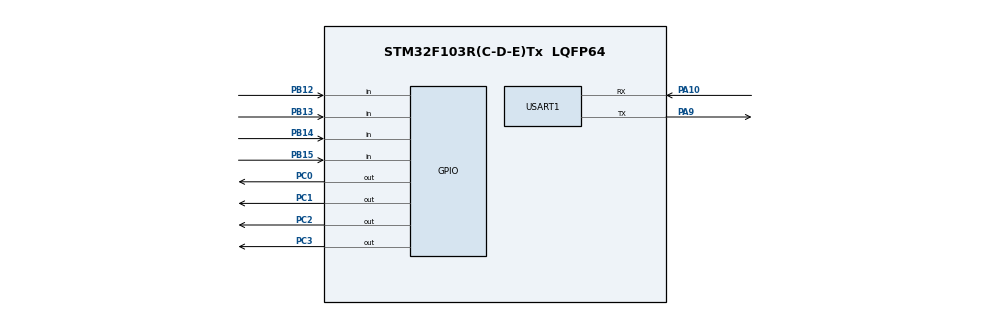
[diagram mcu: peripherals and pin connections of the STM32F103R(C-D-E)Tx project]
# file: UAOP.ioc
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Mcu.Family=STM32F1
Mcu.Name=STM32F103R(C-D-E)Tx
Mcu.Package=LQFP64
NVIC.PriorityGroup=NVIC_PRIORITYGROUP_4
PA10.Mode=Asynchronous
PA10.Signal=USART1_RX
PA9.Mode=Asynchronous
PA9.Signal=USART1_TX
PB12.Signal=GPIO_Input
PB13.Signal=GPIO_Input
PB14.Signal=GPIO_Input
PB15.Signal=GPIO_Input
PC0.PinState=GPIO_PIN_SET
PC0.Signal=GPIO_Output
PC1.PinState=GPIO_PIN_SET
PC1.Signal=GPIO_Output
PC2.PinState=GPIO_PIN_SET
PC2.Signal=GPIO_Output
PC3.PinState=GPIO_PIN_SET
PC3.Signal=GPIO_Output
PD0-OSC_IN.Signal=RCC_OSC_IN
ProjectManager.HeapSize=0x200
ProjectManager.StackSize=0x400
ProjectManager.TargetToolchain=STM32CubeIDE
RCC.APB1Freq_Value=8000000
RCC.APB2Freq_Value=8000000
USART1.VirtualMode=VM_ASYNC
VP_SYS_VS_ND.Mode=No_Debug
VP_TIM1_VS_ClockSourceINT.Mode=Internal
VP_TIM1_VS_ClockSourceITR.Mode=TriggerSource_ITR0
VP_TIM1_VS_ControllerModeTrigger.Mode=Trigger Mode
board=custom

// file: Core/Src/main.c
/* USER CODE BEGIN Header */
/**
  ******************************************************************************
  * @file           : main.c
  * @brief          : Main program body
  ******************************************************************************
  * @attention
  *
  * Copyright (c) 2024 STMicroelectronics.
  * All rights reserved.
  *
  * This software is licensed under terms that can be found in the LICENSE file
  * in the root directory of this software component.
  * If no LICENSE file comes with this software, it is provided AS-IS.
  *
  ******************************************************************************
  */
/* USER CODE END Header */
#include "main.h"
#include "stm32f1xx_hal.h"
#include <string.h>
#include <stdio.h>
#include <ctype.h>

TIM_HandleTypeDef htim1;

UART_HandleTypeDef huart1;

/* USER CODE BEGIN PV */
uint32_t time_star = 0;
uint32_t time_end = 0;
uint32_t time_delta = 0;
/* USER CODE END PV */

void SystemClock_Config(void);
static void MX_GPIO_Init(void);
static void MX_TIM1_Init(void);
static void MX_USART1_UART_Init(void);
void trim_whitespace(char *str);

/* USER CODE BEGIN 0 */
#define NUM_SAIDAS 8
#define NUM_ENTRADAS 4

const char *OUT[NUM_SAIDAS] = {"OUT1_ON", "OUT1_OFF", "OUT2_ON", "OUT2_OFF", "OUT3_ON", "OUT3_OFF", "OUT4_ON", "OUT4_OFF"};
const char *INT[NUM_ENTRADAS] = {"IN1", "IN2", "IN3", "IN4"};

/* USER CODE END 0 */

int main(void)
{

  /* MCU Configuration--------------------------------------------------------*/

  /* Reset of all peripherals, Initializes the Flash interface and the Systick. */
  HAL_Init();

  /* Configure the system clock */
  SystemClock_Config();

  /* Initialize all configured peripherals */
  MX_GPIO_Init();
  MX_TIM1_Init();
  MX_USART1_UART_Init();

  /* USER CODE BEGIN 2 */

  char buffer[100];
  uint8_t dado;
  int index = 0;

  HAL_TIM_Base_Start(&htim1);
  /* USER CODE END 2 */

  /* Infinite loop */
  while (1)
  {
	HAL_UART_Receive(&huart1, &dado, 1, HAL_MAX_DELAY);

	if (dado == '\r') // Verifica se é o fim da palavra (Enter)
	{
		buffer[index] = '\0'; // Termina a string
		trim_whitespace(buffer); // Remove espaços em branco e caracteres invisíveis

		int found = 0;
		for (int i = 0; i < NUM_SAIDAS; i++)
		{
			if (strstr(buffer, OUT[i]) != NULL)
			{
				// Ações para as saídas
				switch (i)
				{
					case 0:
						HAL_GPIO_WritePin(GPIOC, GPIO_PIN_0, GPIO_PIN_RESET); //liga saida out1
						break;
					case 1:
						HAL_GPIO_WritePin(GPIOC, GPIO_PIN_0, GPIO_PIN_SET); //desliga saida out1
						break;
					case 2:
						HAL_GPIO_WritePin(GPIOC, GPIO_PIN_1, GPIO_PIN_RESET); //liga saida out2
						break;
					case 3:
						HAL_GPIO_WritePin(GPIOC, GPIO_PIN_1, GPIO_PIN_SET); //desliga saida out2
						break;
					case 4:
						HAL_GPIO_WritePin(GPIOC, GPIO_PIN_2, GPIO_PIN_RESET); //liga saida out3
						break;
					case 5:
						HAL_GPIO_WritePin(GPIOC, GPIO_PIN_2, GPIO_PIN_SET); //desliga saida out3
						break;
					case 6:
						HAL_GPIO_WritePin(GPIOC, GPIO_PIN_3, GPIO_PIN_RESET); //liga saida out4
						break;
					case 7:
						HAL_GPIO_WritePin(GPIOC, GPIO_PIN_3, GPIO_PIN_SET); //desliga saida out4
						break;
					default:
						break;
				}
				char mensagem[50];
				snprintf(mensagem, sizeof(mensagem), "OK: %d\r\n", i);
				HAL_UART_Transmit(&huart1, (uint8_t*)mensagem, strlen(mensagem), HAL_MAX_DELAY);
				found = 1;
				break;
				}
			}

			// Ações para as entradas
			for (int i = 0; i < NUM_ENTRADAS; i++)
			{
				if (strstr(buffer, INT[i]) != NULL)
				{
				GPIO_PinState pinState;
				switch (i)
					{
					case 0:
						pinState = HAL_GPIO_ReadPin(GPIOB, GPIO_PIN_12); // Leitura da entrada IN1
						break;
					case 1:
						pinState = HAL_GPIO_ReadPin(GPIOB, GPIO_PIN_13); // Leitura da entrada IN2
						break;
					case 2:
						pinState = HAL_GPIO_ReadPin(GPIOB, GPIO_PIN_14); // Leitura da entrada IN3
						break;
					case 3:
						pinState = HAL_GPIO_ReadPin(GPIOB, GPIO_PIN_15); // Leitura da entrada IN4
						break;
					default:
						pinState = GPIO_PIN_RESET; // Valor padrão se o índice for inválido
						break;
					}
					char pinMessage[50];
					snprintf(pinMessage, sizeof(pinMessage), "IN%d: %d\r\n", i + 1, pinState);
					HAL_UART_Transmit(&huart1, (uint8_t*)pinMessage, strlen(pinMessage), HAL_MAX_DELAY);
					found = 1;
					break;
				}
			}

			if (!found)
			{
				char mensagem[110];
				snprintf(mensagem, sizeof(mensagem), "NOK: %s\r\n", buffer);
				HAL_UART_Transmit(&huart1, (uint8_t*)mensagem, strlen(mensagem), HAL_MAX_DELAY);

				char erro[50];
				snprintf(erro, sizeof(erro), "Invalid command.\n");
				HAL_UART_Transmit(&huart1, (uint8_t*)erro, strlen(erro), HAL_MAX_DELAY);
			}

			index = 0; // Reseta o índice para a próxima palavra
			memset(buffer, 0, sizeof(buffer)); // Limpa o buffer
		}

		else
		{
			buffer[index++] = dado; // Adiciona o caractere ao buffer
			if (index >= sizeof(buffer) - 1) // Evita overflow do buffer
			{
				index = 0;
				memset(buffer, 0, sizeof(buffer));
			}
		}
  }
}

void trim_whitespace(char *str)
{
	char *end;

	// Trim leading space
	while (isspace((unsigned char)*str)) str++;

	if (*str == 0)  // All spaces?
	return;

	// Trim trailing space
	end = str + strlen(str) - 1;
	while (end > str && isspace((unsigned char)*end)) end--;

	// Write new null terminator
	*(end + 1) = '\0';
}
void SystemClock_Config(void)
{
  RCC_OscInitTypeDef RCC_OscInitStruct = {0};
  RCC_ClkInitTypeDef RCC_ClkInitStruct = {0};

  /** Initializes the RCC Oscillators according to the specified parameters
  * in the RCC_OscInitTypeDef structure.
  */
  RCC_OscInitStruct.OscillatorType = RCC_OSCILLATORTYPE_HSI;
  RCC_OscInitStruct.HSIState = RCC_HSI_ON;
  RCC_OscInitStruct.HSICalibrationValue = RCC_HSICALIBRATION_DEFAULT;
  RCC_OscInitStruct.PLL.PLLState = RCC_PLL_NONE;
  if (HAL_RCC_OscConfig(&RCC_OscInitStruct) != HAL_OK)
  {
    Error_Handler();
  }

  /** Initializes the CPU, AHB and APB buses clocks
  */
  RCC_ClkInitStruct.ClockType = RCC_CLOCKTYPE_HCLK|RCC_CLOCKTYPE_SYSCLK
                              |RCC_CLOCKTYPE_PCLK1|RCC_CLOCKTYPE_PCLK2;
  RCC_ClkInitStruct.SYSCLKSource = RCC_SYSCLKSOURCE_HSI;
  RCC_ClkInitStruct.AHBCLKDivider = RCC_SYSCLK_DIV1;
  RCC_ClkInitStruct.APB1CLKDivider = RCC_HCLK_DIV1;
  RCC_ClkInitStruct.APB2CLKDivider = RCC_HCLK_DIV1;

  if (HAL_RCC_ClockConfig(&RCC_ClkInitStruct, FLASH_LATENCY_0) != HAL_OK)
  {
    Error_Handler();
  }
}

static void MX_TIM1_Init(void)
{

  TIM_ClockConfigTypeDef sClockSourceConfig = {0};
  TIM_SlaveConfigTypeDef sSlaveConfig = {0};
  TIM_MasterConfigTypeDef sMasterConfig = {0};

  htim1.Instance = TIM1;
  htim1.Init.Prescaler = 72 - 1;
  htim1.Init.CounterMode = TIM_COUNTERMODE_UP;
  htim1.Init.Period = 0xFFFFFFFF;
  htim1.Init.ClockDivision = TIM_CLOCKDIVISION_DIV1;
  htim1.Init.RepetitionCounter = 0;
  htim1.Init.AutoReloadPreload = TIM_AUTORELOAD_PRELOAD_DISABLE;
  if (HAL_TIM_Base_Init(&htim1) != HAL_OK)
  {
    Error_Handler();
  }
  sClockSourceConfig.ClockSource = TIM_CLOCKSOURCE_INTERNAL;
  if (HAL_TIM_ConfigClockSource(&htim1, &sClockSourceConfig) != HAL_OK)
  {
    Error_Handler();
  }
  sSlaveConfig.SlaveMode = TIM_SLAVEMODE_TRIGGER;
  sSlaveConfig.InputTrigger = TIM_TS_ITR0;
  if (HAL_TIM_SlaveConfigSynchro(&htim1, &sSlaveConfig) != HAL_OK)
  {
    Error_Handler();
  }
  sMasterConfig.MasterOutputTrigger = TIM_TRGO_RESET;
  sMasterConfig.MasterSlaveMode = TIM_MASTERSLAVEMODE_DISABLE;
  if (HAL_TIMEx_MasterConfigSynchronization(&htim1, &sMasterConfig) != HAL_OK)
  {
    Error_Handler();
  }
}

static void MX_USART1_UART_Init(void)
{

  huart1.Instance = USART1;
  huart1.Init.BaudRate = 115200;
  huart1.Init.WordLength = UART_WORDLENGTH_8B;
  huart1.Init.StopBits = UART_STOPBITS_1;
  huart1.Init.Parity = UART_PARITY_NONE;
  huart1.Init.Mode = UART_MODE_TX_RX;
  huart1.Init.HwFlowCtl = UART_HWCONTROL_NONE;
  huart1.Init.OverSampling = UART_OVERSAMPLING_16;
  if (HAL_UART_Init(&huart1) != HAL_OK)
  {
    Error_Handler();
  }

}

static void MX_GPIO_Init(void)
{
  GPIO_InitTypeDef GPIO_InitStruct = {0};

  /* GPIO Ports Clock Enable */
  __HAL_RCC_GPIOD_CLK_ENABLE();
  __HAL_RCC_GPIOC_CLK_ENABLE();
  __HAL_RCC_GPIOB_CLK_ENABLE();
  __HAL_RCC_GPIOA_CLK_ENABLE();

  /*Configure GPIO pin Output Level */
  HAL_GPIO_WritePin(GPIOC, GPIO_PIN_0|GPIO_PIN_1|GPIO_PIN_2|GPIO_PIN_3, GPIO_PIN_SET);

  /*Configure GPIO pins : PC0 PC1 PC2 PC3 */
  GPIO_InitStruct.Pin = GPIO_PIN_0|GPIO_PIN_1|GPIO_PIN_2|GPIO_PIN_3;
  GPIO_InitStruct.Mode = GPIO_MODE_OUTPUT_PP;
  GPIO_InitStruct.Pull = GPIO_NOPULL;
  GPIO_InitStruct.Speed = GPIO_SPEED_FREQ_LOW;
  HAL_GPIO_Init(GPIOC, &GPIO_InitStruct);

  /*Configure GPIO pins : PB12 PB13 PB14 PB15 */
  GPIO_InitStruct.Pin = GPIO_PIN_12|GPIO_PIN_13|GPIO_PIN_14|GPIO_PIN_15;
  GPIO_InitStruct.Mode = GPIO_MODE_INPUT;
  GPIO_InitStruct.Pull = GPIO_NOPULL;
  HAL_GPIO_Init(GPIOB, &GPIO_InitStruct);

}

void Error_Handler(void)
{
  __disable_irq();
  while (1)
  {
  }
}
